VERSION ""

NS_ :

BS_:

BU_: ECU Motor PowerAux Solar MotorController

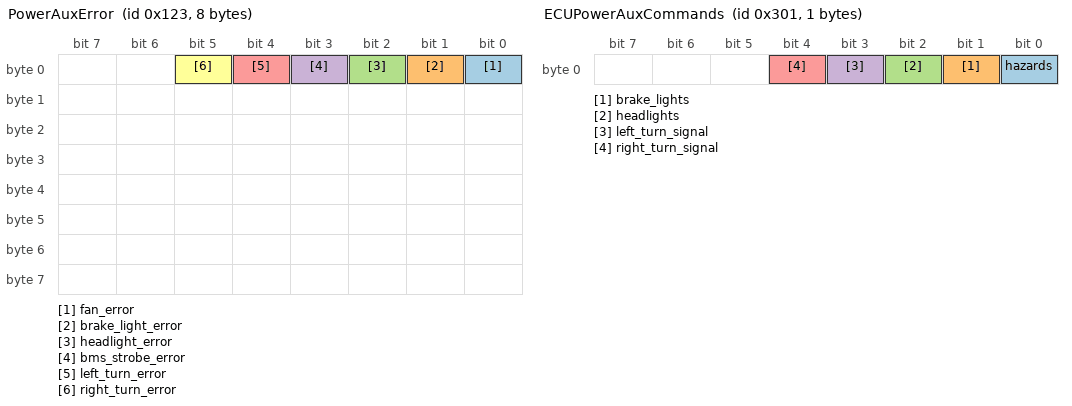
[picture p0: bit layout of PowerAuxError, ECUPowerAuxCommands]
BO_ 291 PowerAuxError: 8 PowerAux
 SG_ fan_error : 0|1@0+ (1,0) [0|0] "" Vector__XXX
 SG_ brake_light_error : 1|1@0+ (1,0) [0|0] "" Vector__XXX
 SG_ headlight_error : 2|1@0+ (1,0) [0|0] "" Vector__XXX
 SG_ bms_strobe_error : 3|1@0+ (1,0) [0|0] "" Vector__XXX
 SG_ left_turn_error : 4|1@0+ (1,0) [0|0] "" Vector__XXX
 SG_ right_turn_error : 5|1@0+ (1,0) [0|0] "" Vector__XXX

BO_ 513 ECUMotorCommands: 4 ECU
 SG_ throttle : 8|9@0+ (1,0) [0|256] "" Vector__XXX
 SG_ regen : 1|9@0+ (1,0) [0|256] "" Vector__XXX
 SG_ cruise_control_speed : 9|8@0+ (1,0) [0|0] "" Vector__XXX
 SG_ cruise_control_en : 26|1@0+ (1,0) [0|0] "" Vector__XXX
 SG_ forward_en : 27|1@0+ (1,0) [0|0] "" Vector__XXX
 SG_ reverse_en : 28|1@0+ (1,0) [0|0] "" Vector__XXX
 SG_ motor_on : 29|1@0+ (1,0) [0|0] "" Vector__XXX

BO_ 769 ECUPowerAuxCommands: 1 ECU
 SG_ hazards : 0|1@0+ (1,0) [0|0] "" Vector__XXX
 SG_ brake_lights : 1|1@0+ (1,0) [0|0] "" Vector__XXX
 SG_ headlights : 2|1@0+ (1,0) [0|0] "" Vector__XXX
 SG_ left_turn_signal : 3|1@0+ (1,0) [0|0] "" Vector__XXX
 SG_ right_turn_signal : 4|1@0+ (1,0) [0|0] "" Vector__XXX

BO_ 1076 SolarCurrent: 2 Solar
 SG_ total_current : -1|16@0+ (1,0) [0|0] "" Vector__XXX

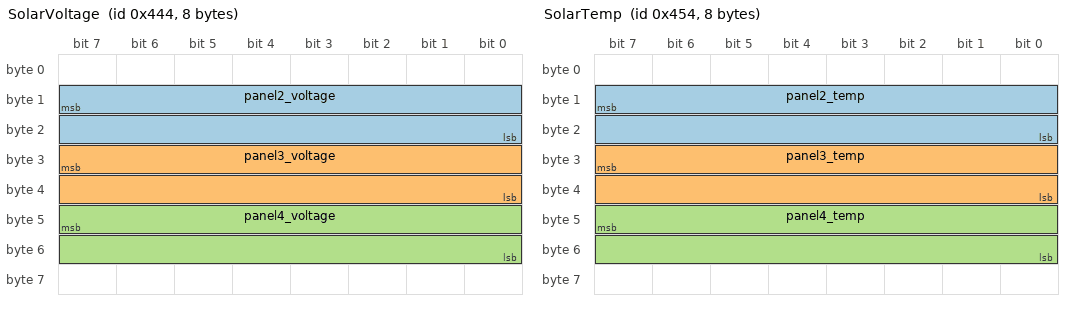
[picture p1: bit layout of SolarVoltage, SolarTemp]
BO_ 1092 SolarVoltage: 8 Solar
 SG_ panel1_voltage : -1|16@0+ (1,0) [0|0] "" Vector__XXX
 SG_ panel2_voltage : 15|16@0+ (1,0) [0|0] "" Vector__XXX
 SG_ panel3_voltage : 31|16@0+ (1,0) [0|0] "" Vector__XXX
 SG_ panel4_voltage : 47|16@0+ (1,0) [0|0] "" Vector__XXX

BO_ 1108 SolarTemp: 8 Solar
 SG_ panel1_temp : -1|16@0+ (1,0) [0|0] "" Vector__XXX
 SG_ panel2_temp : 15|16@0+ (1,0) [0|0] "" Vector__XXX
 SG_ panel3_temp : 31|16@0+ (1,0) [0|0] "" Vector__XXX
 SG_ panel4_temp : 47|16@0+ (1,0) [0|0] "" Vector__XXX

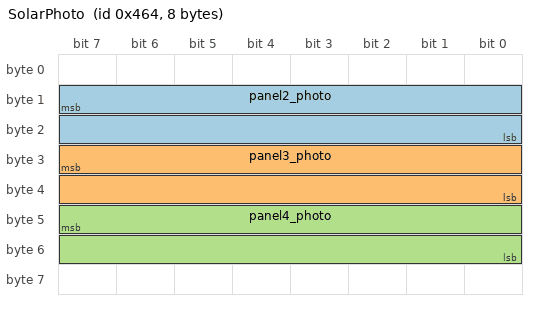
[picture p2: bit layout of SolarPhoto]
BO_ 1124 SolarPhoto: 8 Solar
 SG_ panel1_photo : -1|16@0+ (1,0) [0|0] "" Vector__XXX
 SG_ panel2_photo : 15|16@0+ (1,0) [0|0] "" Vector__XXX
 SG_ panel3_photo : 31|16@0+ (1,0) [0|0] "" Vector__XXX
 SG_ panel4_photo : 47|16@0+ (1,0) [0|0] "" Vector__XXX

BA_DEF_  "BusType" STRING ;
BA_DEF_DEF_  "BusType" "CAN";
